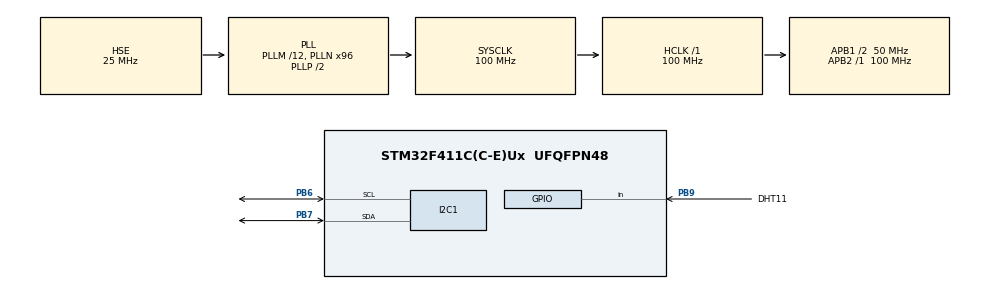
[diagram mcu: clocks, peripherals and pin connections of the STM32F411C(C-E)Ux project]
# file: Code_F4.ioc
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Mcu.Family=STM32F4
Mcu.Name=STM32F411C(C-E)Ux
Mcu.Package=UFQFPN48
NVIC.PriorityGroup=NVIC_PRIORITYGROUP_4
PA13.Mode=Serial_Wire
PA13.Signal=SYS_JTMS-SWDIO
PA14.Mode=Serial_Wire
PA14.Signal=SYS_JTCK-SWCLK
PB6.Mode=I2C
PB6.Signal=I2C1_SCL
PB7.Mode=I2C
PB7.Signal=I2C1_SDA
PB9.GPIO_Label=DHT11
PB9.Signal=GPIO_Input
PH0\ -\ OSC_IN.Mode=HSE-External-Oscillator
PH0\ -\ OSC_IN.Signal=RCC_OSC_IN
PH1\ -\ OSC_OUT.Mode=HSE-External-Oscillator
PH1\ -\ OSC_OUT.Signal=RCC_OSC_OUT
ProjectManager.HeapSize=0x200
ProjectManager.StackSize=0x400
ProjectManager.TargetToolchain=MDK-ARM V5
RCC.48MHZClocksFreq_Value=50000000
RCC.AHBFreq_Value=100000000
RCC.APB1CLKDivider=RCC_HCLK_DIV2
RCC.APB1Freq_Value=50000000
RCC.APB1TimFreq_Value=100000000
RCC.APB2Freq_Value=100000000
RCC.APB2TimFreq_Value=100000000
RCC.CortexFreq_Value=100000000
RCC.HCLKFreq_Value=100000000
RCC.HSE_VALUE=25000000
RCC.HSI_VALUE=16000000
RCC.LSE_VALUE=32768
RCC.PLLM=12
RCC.PLLN=96
RCC.PLLSourceVirtual=RCC_PLLSOURCE_HSE
RCC.SYSCLKFreq_VALUE=100000000
RCC.SYSCLKSource=RCC_SYSCLKSOURCE_PLLCLK
RCC.VCOOutputFreq_Value=200000000
TIM1.Prescaler=71
VP_TIM1_VS_ClockSourceINT.Mode=Internal
board=custom

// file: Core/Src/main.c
/* USER CODE BEGIN Header */
/**
  ******************************************************************************
  * @file           : main.c
  * @brief          : Main program body
  ******************************************************************************
  * @attention
  *
  * Copyright (c) 2023 STMicroelectronics.
  * All rights reserved.
  *
  * This software is licensed under terms that can be found in the LICENSE file
  * in the root directory of this software component.
  * If no LICENSE file comes with this software, it is provided AS-IS.
  *
  ******************************************************************************
  */
/* USER CODE END Header */
#include "main.h"
#include "i2c.h"
#include "tim.h"
#include "gpio.h"

/* USER CODE BEGIN Includes */
#include "CLCD_I2C.h"
#include "string.h"
#include "stdio.h"
/* USER CODE END Includes */

/* USER CODE BEGIN PV */
// DHT11 Variable
uint8_t 	RHI, RHD, TCI, TCD, SUM;
uint32_t 	pMillis, cMillis;
float 		tCelsius = 0;
float 		tFahrenheit = 0;
float 		RH = 0;
// LCD
CLCD_I2C_Name LCD1;
char temp[5], humi[5];
/* USER CODE END PV */

void SystemClock_Config(void);
/* USER CODE BEGIN PFP */
void microDelay(uint16_t delay);
uint8_t DHT11_Start(void);
uint8_t DHT11_Read(void);
/* USER CODE END PFP */

int main(void)
{

  /* MCU Configuration--------------------------------------------------------*/

  /* Reset of all peripherals, Initializes the Flash interface and the Systick. */
  HAL_Init();

  /* Configure the system clock */
  SystemClock_Config();

  /* Initialize all configured peripherals */
  MX_GPIO_Init();
  MX_I2C1_Init();
  MX_TIM1_Init();
  /* USER CODE BEGIN 2 */
	HAL_TIM_Base_Start(&htim1);
	CLCD_I2C_Init(&LCD1,&hi2c1, 0x4E, 16,2);

	CLCD_I2C_SetCursor(&LCD1, 0, 0);
	CLCD_I2C_WriteString(&LCD1, "Nhiet do: ");
	CLCD_I2C_SetCursor(&LCD1, 0, 1);
	CLCD_I2C_WriteString(&LCD1, "Do am: ");
  /* USER CODE END 2 */

  /* Infinite loop */
  /* USER CODE BEGIN WHILE */
  while (1)
  {
		if(DHT11_Start())	{
      RHI = DHT11_Read();
      RHD = DHT11_Read();
      TCI = DHT11_Read();
      TCD = DHT11_Read();
      SUM = DHT11_Read();

			if (RHI + RHD + TCI + TCD == SUM) {
        tCelsius = (float)TCI + (float)(TCD/10.0);
        tFahrenheit = tCelsius * 9/5 + 32;
        RH = (float)RHI + (float)(RHD/10.0);
      }
    }
		CLCD_I2C_SetCursor(&LCD1, 10, 0);
		sprintf(temp, "%f", tCelsius);
		CLCD_I2C_WriteString(&LCD1, temp);
		CLCD_I2C_SetCursor(&LCD1, 7, 1);
		sprintf(humi, "%f", RH);
		CLCD_I2C_WriteString(&LCD1, humi);
    HAL_Delay(500);
    /* USER CODE END WHILE */

  }
}

void SystemClock_Config(void)
{
  RCC_OscInitTypeDef RCC_OscInitStruct = {0};
  RCC_ClkInitTypeDef RCC_ClkInitStruct = {0};

  /** Configure the main internal regulator output voltage
  */
  __HAL_RCC_PWR_CLK_ENABLE();
  __HAL_PWR_VOLTAGESCALING_CONFIG(PWR_REGULATOR_VOLTAGE_SCALE1);

  /** Initializes the RCC Oscillators according to the specified parameters
  * in the RCC_OscInitTypeDef structure.
  */
  RCC_OscInitStruct.OscillatorType = RCC_OSCILLATORTYPE_HSE;
  RCC_OscInitStruct.HSEState = RCC_HSE_ON;
  RCC_OscInitStruct.PLL.PLLState = RCC_PLL_ON;
  RCC_OscInitStruct.PLL.PLLSource = RCC_PLLSOURCE_HSE;
  RCC_OscInitStruct.PLL.PLLM = 12;
  RCC_OscInitStruct.PLL.PLLN = 96;
  RCC_OscInitStruct.PLL.PLLP = RCC_PLLP_DIV2;
  RCC_OscInitStruct.PLL.PLLQ = 4;
  if (HAL_RCC_OscConfig(&RCC_OscInitStruct) != HAL_OK)
  {
    Error_Handler();
  }

  /** Initializes the CPU, AHB and APB buses clocks
  */
  RCC_ClkInitStruct.ClockType = RCC_CLOCKTYPE_HCLK|RCC_CLOCKTYPE_SYSCLK
                              |RCC_CLOCKTYPE_PCLK1|RCC_CLOCKTYPE_PCLK2;
  RCC_ClkInitStruct.SYSCLKSource = RCC_SYSCLKSOURCE_PLLCLK;
  RCC_ClkInitStruct.AHBCLKDivider = RCC_SYSCLK_DIV1;
  RCC_ClkInitStruct.APB1CLKDivider = RCC_HCLK_DIV2;
  RCC_ClkInitStruct.APB2CLKDivider = RCC_HCLK_DIV1;

  if (HAL_RCC_ClockConfig(&RCC_ClkInitStruct, FLASH_LATENCY_3) != HAL_OK)
  {
    Error_Handler();
  }
}

/* USER CODE BEGIN 4 */
void microDelay(uint16_t delay) {
  __HAL_TIM_SET_COUNTER(&htim1, 0);
  while (__HAL_TIM_GET_COUNTER(&htim1) < delay);
}

uint8_t DHT11_Start(void) {
  uint8_t Response = 0;
  GPIO_InitTypeDef GPIO_InitStructPrivate = {0};
  GPIO_InitStructPrivate.Pin = DHT11_Pin;
  GPIO_InitStructPrivate.Mode = GPIO_MODE_OUTPUT_PP;
  GPIO_InitStructPrivate.Speed = GPIO_SPEED_FREQ_LOW;
  GPIO_InitStructPrivate.Pull = GPIO_NOPULL;
  HAL_GPIO_Init(DHT11_GPIO_Port, &GPIO_InitStructPrivate);
  HAL_GPIO_WritePin (DHT11_GPIO_Port, DHT11_Pin, GPIO_PIN_RESET);
  HAL_Delay(20);
  HAL_GPIO_WritePin (DHT11_GPIO_Port, DHT11_Pin, GPIO_PIN_SET);
  microDelay (30);
  GPIO_InitStructPrivate.Mode = GPIO_MODE_INPUT;
  GPIO_InitStructPrivate.Pull = GPIO_PULLUP;
  HAL_GPIO_Init(DHT11_GPIO_Port, &GPIO_InitStructPrivate);
  microDelay (40);

  if (!(HAL_GPIO_ReadPin (DHT11_GPIO_Port, DHT11_Pin))) {
    microDelay (80);
    if ((HAL_GPIO_ReadPin (DHT11_GPIO_Port, DHT11_Pin))) Response = 1;
  }
  pMillis = HAL_GetTick();
  cMillis = HAL_GetTick();

	while ((HAL_GPIO_ReadPin (DHT11_GPIO_Port, DHT11_Pin)) && pMillis + 2 > cMillis) {
    cMillis = HAL_GetTick();
  }
  return Response;
}

// Read Data
uint8_t DHT11_Read(void) {
  uint8_t a,b;
  for (a=0;a<8;a++) {
    pMillis = HAL_GetTick();
    cMillis = HAL_GetTick();
    while (!(HAL_GPIO_ReadPin (DHT11_GPIO_Port, DHT11_Pin)) && pMillis + 2 > cMillis)
      cMillis = HAL_GetTick();
    microDelay (40);
    if (!(HAL_GPIO_ReadPin (DHT11_GPIO_Port, DHT11_Pin)))
      b&= ~(1<<(7-a));
    else
      b|= (1<<(7-a));
    pMillis = HAL_GetTick();
    cMillis = HAL_GetTick();
    while ((HAL_GPIO_ReadPin (DHT11_GPIO_Port, DHT11_Pin)) && pMillis + 2 > cMillis)
      cMillis = HAL_GetTick();
  }
  return b;
}
/* USER CODE END 4 */

void Error_Handler(void)
{
  __disable_irq();
  while (1)
  {
  }
}
